AUTOSAR XML (schema 00046)
package /ComponentTypes
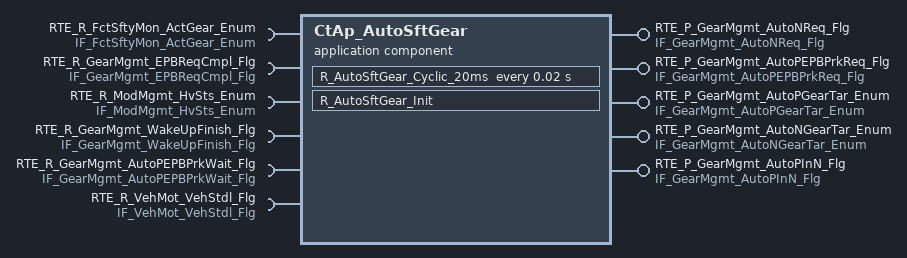
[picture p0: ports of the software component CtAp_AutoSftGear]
  application sw component type CtAp_AutoSftGear
    5 x require port:
      RTE_R_FctSftyMon_ActGear_Enum: nonqueued-receiver-com-spec{data-element=tec_FctSftyMon_ActGear_Enum, filter=data-filter-type=ALWAYS, init-value=0}, required-interface=IF_FctSftyMon_ActGear_Enum
      RTE_R_GearMgmt_EPBReqCmpl_Flg: nonqueued-receiver-com-spec{data-element=tec_GearMgmt_EPBReqCmpl_Flg, filter=data-filter-type=ALWAYS, init-value=0}, required-interface=IF_GearMgmt_EPBReqCmpl_Flg
      RTE_R_ModMgmt_HvSts_Enum: nonqueued-receiver-com-spec{data-element=tec_ModMgmt_HvSts_Enum, filter=data-filter-type=ALWAYS, init-value=0}, required-interface=IF_ModMgmt_HvSts_Enum
      RTE_R_GearMgmt_WakeUpFinish_Flg: nonqueued-receiver-com-spec{data-element=tec_GearMgmt_WakeUpFinish_Flg, filter=data-filter-type=ALWAYS, init-value=0}, required-interface=IF_GearMgmt_WakeUpFinish_Flg
      RTE_R_GearMgmt_AutoPEPBPrkWait_Flg: nonqueued-receiver-com-spec{data-element=tec_GearMgmt_AutoPEPBPrkWait_Flg, filter=data-filter-type=ALWAYS, init-value=0}, required-interface=IF_GearMgmt_AutoPEPBPrkWait_Flg
    5 x provide port:
      RTE_P_GearMgmt_AutoNReq_Flg: nonqueued-sender-com-spec{data-element=tec_GearMgmt_AutoNReq_Flg, init-value=0}, provided-interface=IF_GearMgmt_AutoNReq_Flg
      RTE_P_GearMgmt_AutoPEPBPrkReq_Flg: nonqueued-sender-com-spec{data-element=tec_GearMgmt_AutoPEPBPrkReq_Flg, init-value=0}, provided-interface=IF_GearMgmt_AutoPEPBPrkReq_Flg
      RTE_P_GearMgmt_AutoPGearTar_Enum: nonqueued-sender-com-spec{data-element=tec_GearMgmt_AutoPGearTar_Enum, init-value=0}, provided-interface=IF_GearMgmt_AutoPGearTar_Enum
      RTE_P_GearMgmt_AutoNGearTar_Enum: nonqueued-sender-com-spec{data-element=tec_GearMgmt_AutoNGearTar_Enum, init-value=0}, provided-interface=IF_GearMgmt_AutoNGearTar_Enum
      RTE_P_GearMgmt_AutoPInN_Flg: nonqueued-sender-com-spec{data-element=tec_GearMgmt_AutoPInN_Flg, init-value=0}, provided-interface=IF_GearMgmt_AutoPInN_Flg
    require port RTE_R_VehMot_VehStdl_Flg: nonqueued-receiver-com-spec{data-element=tec_VehMot_VehStdl_Flg, filter=data-filter-type=ALWAYS, init-value=0}, required-interface=IF_VehMot_VehStdl_Flg
    behavior CtAp_AutoSftGear_InternalBehavior
      timing event TMT_R_AutoSftGear_Cyclic_20ms: start-on-event=R_AutoSftGear_Cyclic_20ms, period=0.02
      init event CtAp_AutoSftGear_InitEvent: start-on-event=R_AutoSftGear_Init
      runnable R_AutoSftGear_Cyclic_20ms
        data-receive-point-by-arguments:
          6 x access:
            REC_RTE_R_FctSftyMon_ActGear_Enum_tec_FctSftyMon_ActGear_Enum: accessed-variable=RTE_R_FctSftyMon_ActGear_Enum.tec_FctSftyMon_ActGear_Enum
            REC_RTE_R_GearMgmt_AutoPEPBPrkWait_Flg_tec_GearMgmt_AutoPEPBPrkWait_Flg: accessed-variable=RTE_R_GearMgmt_AutoPEPBPrkWait_Flg.tec_GearMgmt_AutoPEPBPrkWait_Flg
            REC_RTE_R_GearMgmt_EPBReqCmpl_Flg_tec_GearMgmt_EPBReqCmpl_Flg: accessed-variable=RTE_R_GearMgmt_EPBReqCmpl_Flg.tec_GearMgmt_EPBReqCmpl_Flg
            REC_RTE_R_GearMgmt_WakeUpFinish_Flg_tec_GearMgmt_WakeUpFinish_Flg: accessed-variable=RTE_R_GearMgmt_WakeUpFinish_Flg.tec_GearMgmt_WakeUpFinish_Flg
            REC_RTE_R_ModMgmt_HvSts_Enum_tec_ModMgmt_HvSts_Enum: accessed-variable=RTE_R_ModMgmt_HvSts_Enum.tec_ModMgmt_HvSts_Enum
            REC_RTE_R_VehMot_VehStdl_Flg_tec_VehMot_VehStdl_Flg: accessed-variable=RTE_R_VehMot_VehStdl_Flg.tec_VehMot_VehStdl_Flg
        data-send-points:
          5 x access:
            SEND_RTE_P_GearMgmt_AutoNGearTar_Enum_tec_GearMgmt_AutoNGearTar_Enum: accessed-variable=RTE_P_GearMgmt_AutoNGearTar_Enum.tec_GearMgmt_AutoNGearTar_Enum
            SEND_RTE_P_GearMgmt_AutoNReq_Flg_tec_GearMgmt_AutoNReq_Flg: accessed-variable=RTE_P_GearMgmt_AutoNReq_Flg.tec_GearMgmt_AutoNReq_Flg
            SEND_RTE_P_GearMgmt_AutoPEPBPrkReq_Flg_tec_GearMgmt_AutoPEPBPrkReq_Flg: accessed-variable=RTE_P_GearMgmt_AutoPEPBPrkReq_Flg.tec_GearMgmt_AutoPEPBPrkReq_Flg
            SEND_RTE_P_GearMgmt_AutoPGearTar_Enum_tec_GearMgmt_AutoPGearTar_Enum: accessed-variable=RTE_P_GearMgmt_AutoPGearTar_Enum.tec_GearMgmt_AutoPGearTar_Enum
            SEND_RTE_P_GearMgmt_AutoPInN_Flg_tec_GearMgmt_AutoPInN_Flg: accessed-variable=RTE_P_GearMgmt_AutoPInN_Flg.tec_GearMgmt_AutoPInN_Flg
      runnable R_AutoSftGear_Init
  swc implementation CtAp_AutoSftGear_Implementation: behavior=CtAp_AutoSftGear_InternalBehavior
